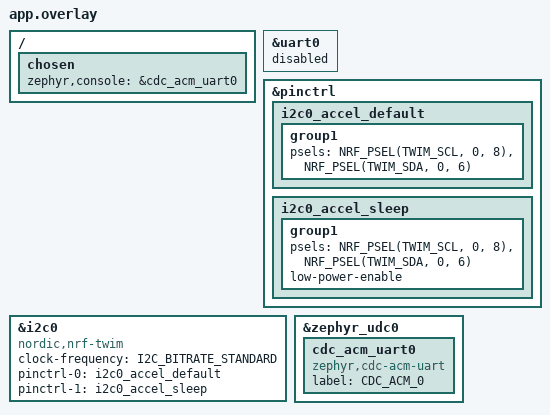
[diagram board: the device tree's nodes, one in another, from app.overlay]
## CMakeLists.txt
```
cmake_minimum_required(VERSION 3.20.0)

set(DTC_OVERLAY_FILE
    "${CMAKE_CURRENT_SOURCE_DIR}/app.overlay"
)

find_package(Zephyr REQUIRED HINTS $ENV{ZEPHYR_BASE})

project(DK_Board)

target_include_directories(app PRIVATE include)

target_sources(app PRIVATE
    src/main.c
    src/accel_app.c
    src/lis2dh.c
)
```

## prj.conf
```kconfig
# GPIO
CONFIG_GPIO=y

# I2C
CONFIG_I2C=y
CONFIG_PINCTRL=y

# USB CDC ACM - New USB Stack
CONFIG_USB_DEVICE_STACK_NEXT=y
CONFIG_CDC_ACM_SERIAL_INITIALIZE_AT_BOOT=y

# Serial
CONFIG_SERIAL=y
CONFIG_UART_LINE_CTRL=y

# USB Console
CONFIG_CONSOLE=y
CONFIG_UART_CONSOLE=y
CONFIG_STDOUT_CONSOLE=y
CONFIG_PRINTK=y

# Logging
CONFIG_LOG=n
```

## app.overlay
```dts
#include <zephyr/dt-bindings/i2c/i2c.h>
#include <zephyr/dt-bindings/pinctrl/nrf-pinctrl.h>

/ {
    chosen {
        zephyr,console = &cdc_acm_uart0;
    };
};

/* Disable UART0 to release P0.08 and P0.06 */
&uart0 {
    status = "disabled";
};

/* I2C pin configuration */
&pinctrl {
    i2c0_accel_default: i2c0_accel_default {
        group1 {
            psels = <NRF_PSEL(TWIM_SCL, 0, 8)>,
                    <NRF_PSEL(TWIM_SDA, 0, 6)>;
        };
    };

    i2c0_accel_sleep: i2c0_accel_sleep {
        group1 {
            psels = <NRF_PSEL(TWIM_SCL, 0, 8)>,
                    <NRF_PSEL(TWIM_SDA, 0, 6)>;
            low-power-enable;
        };
    };
};

/* LIS2DH I2C interface */
&i2c0 {
    compatible = "nordic,nrf-twim";
    status = "okay";

    clock-frequency = <I2C_BITRATE_STANDARD>;

    pinctrl-0 = <&i2c0_accel_default>;
    pinctrl-1 = <&i2c0_accel_sleep>;
    pinctrl-names = "default", "sleep";
};

/* USB CDC ACM virtual COM port */
&zephyr_udc0 {
    status = "okay";

    cdc_acm_uart0: cdc_acm_uart0 {
        compatible = "zephyr,cdc-acm-uart";
        label = "CDC_ACM_0";
        status = "okay";
    };
};
```

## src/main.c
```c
/**
 * @file main.c
 * @brief Start the reusable LIS2DH DK board validation application.
 */
#include <zephyr/sys/printk.h>

#include "accel_app.h"

int main(void)
{
    int ret = accel_app_init();
    if (ret < 0) {
        printk("[APP] Initialization failed (%d)\r\n", ret);
    }

    return ret;
}
```

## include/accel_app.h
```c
/**
 * @file accel_app.h
 * @brief Board-specific LIS2DH validation application interface.
 */
#ifndef ACCEL_APP_H_
#define ACCEL_APP_H_

/**
 * @brief Initialize LED, I2C adapter, and periodic Zephyr kernel timers.
 * @retval 0 Success.
 * @retval -ENODEV Required board peripheral is unavailable.
 * @return Negative GPIO error if LED setup fails.
 * @note USB CDC ACM is initialized automatically through prj.conf.
 */
int accel_app_init(void);

#endif /* ACCEL_APP_H_ */
```

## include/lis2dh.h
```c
/**
 * @file lis2dh.h
 * @brief Portable LIS2DH/LIS2DH12 acceleration sensor interface.
 */
#ifndef LIS2DH_H_
#define LIS2DH_H_

#include <stdbool.h>
#include <stddef.h>
#include <stdint.h>

#define LIS2DH_WHO_AM_I_VALUE 0x33U

typedef int (*lis2dh_read_fn_t)(void *p_context, uint8_t i2c_address,
                                uint8_t register_address, uint8_t *p_data,
                                size_t size_bytes);

typedef int (*lis2dh_write_fn_t)(void *p_context, uint8_t i2c_address,
                                 uint8_t register_address, uint8_t value);

typedef struct {
    lis2dh_read_fn_t read;
    lis2dh_write_fn_t write;
    void *p_context;
} lis2dh_bus_t;

typedef struct {
    lis2dh_bus_t bus;
    uint8_t i2c_address;
    bool is_initialized;
} lis2dh_device_t;

typedef struct {
    int16_t x_mg;
    int16_t y_mg;
    int16_t z_mg;
} lis2dh_sample_t;

/**
 * @brief Probe 0x18/0x19 and configure 100 Hz, +/-2 g, high-resolution mode.
 * @param[out] p_device Device context; must not be NULL.
 * @param[in] p_bus Caller-owned bus callbacks; must remain valid.
 * @retval 0 Success.
 * @retval -EINVAL Invalid arguments.
 * @retval -ENODEV Device not found or unexpected WHO_AM_I.
 * @return Negative bus error if register configuration fails.
 * @note Called from a thread/work context; never from an ISR.
 */
int lis2dh_init(lis2dh_device_t *p_device, const lis2dh_bus_t *p_bus);

/**
 * @brief Read XYZ acceleration in milli-g (mg).
 * @param[in] p_device Initialized device context.
 * @param[out] p_sample Output sample, unchanged on failure.
 * @retval 0 Success.
 * @retval -EINVAL Invalid arguments.
 * @retval -ENODEV Device is not initialized.
 * @return Negative bus error on I2C transfer failure.
 * @note Assumes the sensor remains in the configured +/-2 g, HR mode.
 * @note Caller synchronizes concurrent access, if necessary.
 */
int lis2dh_read_accel(lis2dh_device_t *p_device, lis2dh_sample_t *p_sample);

#endif /* LIS2DH_H_ */
```

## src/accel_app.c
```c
/**
 * @file accel_app.c
 * @brief Non-blocking test scheduler, I2C adapter, USB output, and heartbeat LED.
 */
#include "accel_app.h"

#include <errno.h>
#include <stdbool.h>
#include <stddef.h>
#include <stdint.h>

#include <zephyr/device.h>
#include <zephyr/drivers/gpio.h>
#include <zephyr/drivers/i2c.h>
#include <zephyr/drivers/uart.h>
#include <zephyr/kernel.h>
#include <zephyr/sys/printk.h>

#include "lis2dh.h"

#define ACCEL_SAMPLE_PERIOD_MS       20U
#define ACCEL_LED_TOGGLE_PERIOD_MS   500U
#define ACCEL_ERROR_REPORT_INTERVAL 10U
/* Use board-defined node labels instead of custom aliases. */
#define ACCEL_I2C_NODE              DT_NODELABEL(i2c0)
#define ACCEL_LED_NODE              DT_NODELABEL(led0)
#define ACCEL_USB_NODE              DT_NODELABEL(cdc_acm_uart0)

/* Fail early if the required overlay or board target is not applied. */
#if !DT_NODE_HAS_STATUS(ACCEL_I2C_NODE, okay)
#error "I2C0 disabled: app.overlay missing or incorrect board selected"
#endif

#if !DT_NODE_EXISTS(ACCEL_LED_NODE)
#error "Missing led0 board node: select raytac_mdbt50q_db_40/nrf52840"
#endif

#if !DT_NODE_HAS_STATUS(ACCEL_USB_NODE, okay)
#error "Missing USB CDC node: ensure DK_Board/app.overlay is applied"
#endif

static const struct device *s_p_i2c_device = DEVICE_DT_GET(ACCEL_I2C_NODE);
static const struct device *s_p_usb_console = DEVICE_DT_GET(DT_CHOSEN(zephyr_console));
static const struct gpio_dt_spec s_led = GPIO_DT_SPEC_GET(ACCEL_LED_NODE, gpios);

static lis2dh_device_t s_lis2dh_device;
static bool s_is_sensor_ready;
static bool s_was_usb_connected;
static uint32_t s_error_report_count;
static struct k_timer s_led_timer;
static struct k_timer s_sensor_timer;
static struct k_work s_led_work;
static struct k_work s_sensor_work;

static int accel_app_bus_read(void *p_context, uint8_t i2c_address,
                              uint8_t register_address, uint8_t *p_data,
                              size_t size_bytes);
static int accel_app_bus_write(void *p_context, uint8_t i2c_address,
                               uint8_t register_address, uint8_t value);
static bool accel_app_is_usb_connected(void);
static void accel_app_led_timer_handler(struct k_timer *p_timer);
static void accel_app_sensor_timer_handler(struct k_timer *p_timer);
static void accel_app_led_work_handler(struct k_work *p_work);
static void accel_app_sensor_work_handler(struct k_work *p_work);

int accel_app_init(void)
{
    if (!device_is_ready(s_led.port) || !device_is_ready(s_p_i2c_device)) {
        return -ENODEV;
    }

    int ret = gpio_pin_configure_dt(&s_led, GPIO_OUTPUT_INACTIVE);
    if (ret < 0) {
        return ret;
    }

    k_work_init(&s_led_work, accel_app_led_work_handler);
    k_work_init(&s_sensor_work, accel_app_sensor_work_handler);
    k_timer_init(&s_led_timer, accel_app_led_timer_handler, NULL);
    k_timer_init(&s_sensor_timer, accel_app_sensor_timer_handler, NULL);

    /* Timer callbacks only enqueue work; GPIO, I2C, and USB run in thread context. */
    k_timer_start(&s_led_timer, K_MSEC(ACCEL_LED_TOGGLE_PERIOD_MS),
                  K_MSEC(ACCEL_LED_TOGGLE_PERIOD_MS));
    k_timer_start(&s_sensor_timer, K_MSEC(ACCEL_SAMPLE_PERIOD_MS),
                  K_MSEC(ACCEL_SAMPLE_PERIOD_MS));

    return 0;
}

static int accel_app_bus_read(void *p_context, uint8_t i2c_address,
                              uint8_t register_address, uint8_t *p_data,
                              size_t size_bytes)
{
    if ((p_context == NULL) || (p_data == NULL) || (size_bytes == 0U)) {
        return -EINVAL;
    }

    const struct device *p_bus = p_context;

    return i2c_write_read(p_bus, i2c_address, &register_address,
                          sizeof(register_address), p_data, size_bytes);
}

static int accel_app_bus_write(void *p_context, uint8_t i2c_address,
                               uint8_t register_address, uint8_t value)
{
    if (p_context == NULL) {
        return -EINVAL;
    }

    const struct device *p_bus = p_context;
    return i2c_reg_write_byte(p_bus, i2c_address, register_address, value);
}

static bool accel_app_is_usb_connected(void)
{
    if (!device_is_ready(s_p_usb_console)) {
        return false;
    }

    uint32_t dtr = 0U;
    int ret = uart_line_ctrl_get(s_p_usb_console, UART_LINE_CTRL_DTR, &dtr);

    return (ret == 0) && (dtr != 0U);
}

static void accel_app_led_timer_handler(struct k_timer *p_timer)
{
    ARG_UNUSED(p_timer);
    (void)k_work_submit(&s_led_work);
}

static void accel_app_sensor_timer_handler(struct k_timer *p_timer)
{
    ARG_UNUSED(p_timer);
    (void)k_work_submit(&s_sensor_work);
}

static void accel_app_led_work_handler(struct k_work *p_work)
{
    ARG_UNUSED(p_work);
    (void)gpio_pin_toggle_dt(&s_led);
}

static void accel_app_sensor_work_handler(struct k_work *p_work)
{
    ARG_UNUSED(p_work);

    bool is_usb_connected = accel_app_is_usb_connected();
    if (is_usb_connected && !s_was_usb_connected) {
        printk("\r\n[LIS2DH] DK test started\r\n");
        printk("[LIS2DH] I2C SCL=P0.08, SDA=P0.06; LED=P0.13\r\n");
        printk("[LIS2DH] Sensor=100Hz/2g/HR; Output=100ms\r\n");
        if (s_is_sensor_ready) {
            printk("[LIS2DH] Ready at 0x%02X (WHO_AM_I=0x33)\r\n",
                   s_lis2dh_device.i2c_address);
        }
    }
    s_was_usb_connected = is_usb_connected;

    if (!s_is_sensor_ready) {
        const lis2dh_bus_t bus = {
            .read = accel_app_bus_read,
            .write = accel_app_bus_write,
            .p_context = (void *)s_p_i2c_device,
        };

        int ret = lis2dh_init(&s_lis2dh_device, &bus);
        if (ret < 0) {
            s_error_report_count++;
            if (is_usb_connected &&
                (s_error_report_count % ACCEL_ERROR_REPORT_INTERVAL == 0U)) {
                printk("[LIS2DH] Probe failed (%d); check wiring/SA0\r\n", ret);
            }
            return;
        }

        s_is_sensor_ready = true;
        s_error_report_count = 0U;
        if (is_usb_connected) {
            printk("[LIS2DH] Ready at 0x%02X (WHO_AM_I=0x33)\r\n",
                   s_lis2dh_device.i2c_address);
        }
    }

    lis2dh_sample_t sample = {0};
    int ret = lis2dh_read_accel(&s_lis2dh_device, &sample);
    if (ret < 0) {
        s_error_report_count++;
        if (is_usb_connected &&
            (s_error_report_count % ACCEL_ERROR_REPORT_INTERVAL == 0U)) {
            printk("[LIS2DH] Read failed (%d)\r\n", ret);
        }
        return;
    }

    s_error_report_count = 0U;
    if (is_usb_connected) {
        printk("[%u ms] X=%d mg, Y=%d mg, Z=%d mg\r\n",
               k_uptime_get_32(), sample.x_mg, sample.y_mg, sample.z_mg);
    }
}
```

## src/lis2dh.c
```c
/**
 * @file lis2dh.c
 * @brief Register-level LIS2DH driver with injected bus callbacks.
 */
#include "lis2dh.h"

#include <errno.h>
#include <stddef.h>

#define LIS2DH_I2C_ADDRESS_LOW       0x18U
#define LIS2DH_I2C_ADDRESS_HIGH      0x19U
#define LIS2DH_REG_WHO_AM_I          0x0FU
#define LIS2DH_REG_CTRL1             0x20U
#define LIS2DH_REG_CTRL4             0x23U
#define LIS2DH_REG_OUT_X_L           0x28U
#define LIS2DH_REG_AUTO_INCREMENT    0x80U
#define LIS2DH_CTRL1_POWER_DOWN      0x00U
#define LIS2DH_CTRL1_ODR_100HZ_XYZ   0x57U
#define LIS2DH_CTRL4_BDU_HR_2G       0x88U
#define LIS2DH_AXIS_BUFFER_SIZE      6U
#define LIS2DH_SHIFT_BITS            4U
#define LIS2DH_12BIT_SIGN_BIT        0x0800U
#define LIS2DH_12BIT_SIGN_EXTEND     4096

static int16_t lis2dh_decode_mg(uint8_t low_byte, uint8_t high_byte);

int lis2dh_init(lis2dh_device_t *p_device, const lis2dh_bus_t *p_bus)
{
    if ((p_device == NULL) || (p_bus == NULL) ||
        (p_bus->read == NULL) || (p_bus->write == NULL)) {
        return -EINVAL;
    }

    p_device->is_initialized = false;
    p_device->bus = *p_bus;
    p_device->i2c_address = 0U;

    const uint8_t addresses[] = {
        LIS2DH_I2C_ADDRESS_LOW,
        LIS2DH_I2C_ADDRESS_HIGH,
    };
    uint8_t who_am_i = 0U;
    bool is_found = false;

    for (size_t i = 0U; i < (sizeof(addresses) / sizeof(addresses[0])); i++) {
        int ret = p_bus->read(p_bus->p_context, addresses[i],
                              LIS2DH_REG_WHO_AM_I, &who_am_i, sizeof(who_am_i));
        if ((ret == 0) && (who_am_i == LIS2DH_WHO_AM_I_VALUE)) {
            p_device->i2c_address = addresses[i];
            is_found = true;
            break;
        }
    }

    if (!is_found) {
        return -ENODEV;
    }

    /* Configure HR and BDU before enabling measurement output. */
    int ret = p_bus->write(p_bus->p_context, p_device->i2c_address,
                           LIS2DH_REG_CTRL1, LIS2DH_CTRL1_POWER_DOWN);
    if (ret < 0) {
        return ret;
    }

    ret = p_bus->write(p_bus->p_context, p_device->i2c_address,
                       LIS2DH_REG_CTRL4, LIS2DH_CTRL4_BDU_HR_2G);
    if (ret < 0) {
        return ret;
    }

    ret = p_bus->write(p_bus->p_context, p_device->i2c_address,
                       LIS2DH_REG_CTRL1, LIS2DH_CTRL1_ODR_100HZ_XYZ);
    if (ret < 0) {
        return ret;
    }

    p_device->is_initialized = true;
    return 0;
}

int lis2dh_read_accel(lis2dh_device_t *p_device, lis2dh_sample_t *p_sample)
{
    if ((p_device == NULL) || (p_sample == NULL)) {
        return -EINVAL;
    }

    if (!p_device->is_initialized) {
        return -ENODEV;
    }

    uint8_t axis_bytes[LIS2DH_AXIS_BUFFER_SIZE] = {0};
    uint8_t start_register = LIS2DH_REG_OUT_X_L | LIS2DH_REG_AUTO_INCREMENT;

    int ret = p_device->bus.read(p_device->bus.p_context, p_device->i2c_address,
                                 start_register, axis_bytes, sizeof(axis_bytes));
    if (ret < 0) {
        return ret;
    }

    lis2dh_sample_t sample = {
        .x_mg = lis2dh_decode_mg(axis_bytes[0], axis_bytes[1]),
        .y_mg = lis2dh_decode_mg(axis_bytes[2], axis_bytes[3]),
        .z_mg = lis2dh_decode_mg(axis_bytes[4], axis_bytes[5]),
    };

    *p_sample = sample;
    return 0;
}

static int16_t lis2dh_decode_mg(uint8_t low_byte, uint8_t high_byte)
{
    uint16_t packed = (uint16_t)low_byte | ((uint16_t)high_byte << 8U);
    uint16_t raw_12bit = packed >> LIS2DH_SHIFT_BITS;

    /* Explicit 12-bit sign extension avoids implementation-defined signed shifts. */
    int32_t signed_value = ((raw_12bit & LIS2DH_12BIT_SIGN_BIT) != 0U)
        ? (int32_t)raw_12bit - LIS2DH_12BIT_SIGN_EXTEND
        : (int32_t)raw_12bit;

    /* At +/-2 g in HR mode, one 12-bit LSB equals approximately 1 mg. */
    return (int16_t)signed_value;
}
```
